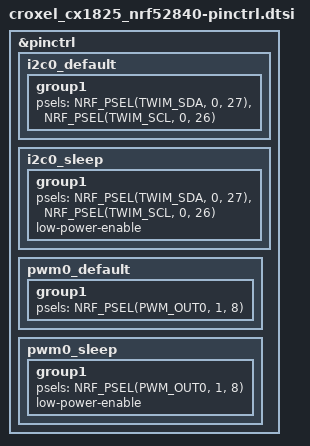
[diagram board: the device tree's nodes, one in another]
/*
 * Copyright (c) 2024 Luis Ubieda
 * SPDX-License-Identifier: Apache-2.0
 */

&pinctrl {

	i2c0_default: i2c0_default {
		group1 {
			psels = <NRF_PSEL(TWIM_SDA, 0, 27)>,
				<NRF_PSEL(TWIM_SCL, 0, 26)>;
		};
	};

	i2c0_sleep: i2c0_sleep {
		group1 {
			psels = <NRF_PSEL(TWIM_SDA, 0, 27)>,
				<NRF_PSEL(TWIM_SCL, 0, 26)>;
			low-power-enable;
		};
	};

	pwm0_default: pwm0_default {
		group1 {
			psels = <NRF_PSEL(PWM_OUT0, 1, 8)>;
		};
	};

	pwm0_sleep: pwm0_sleep {
		group1 {
			psels = <NRF_PSEL(PWM_OUT0, 1, 8)>;
			low-power-enable;
		};
	};
};
